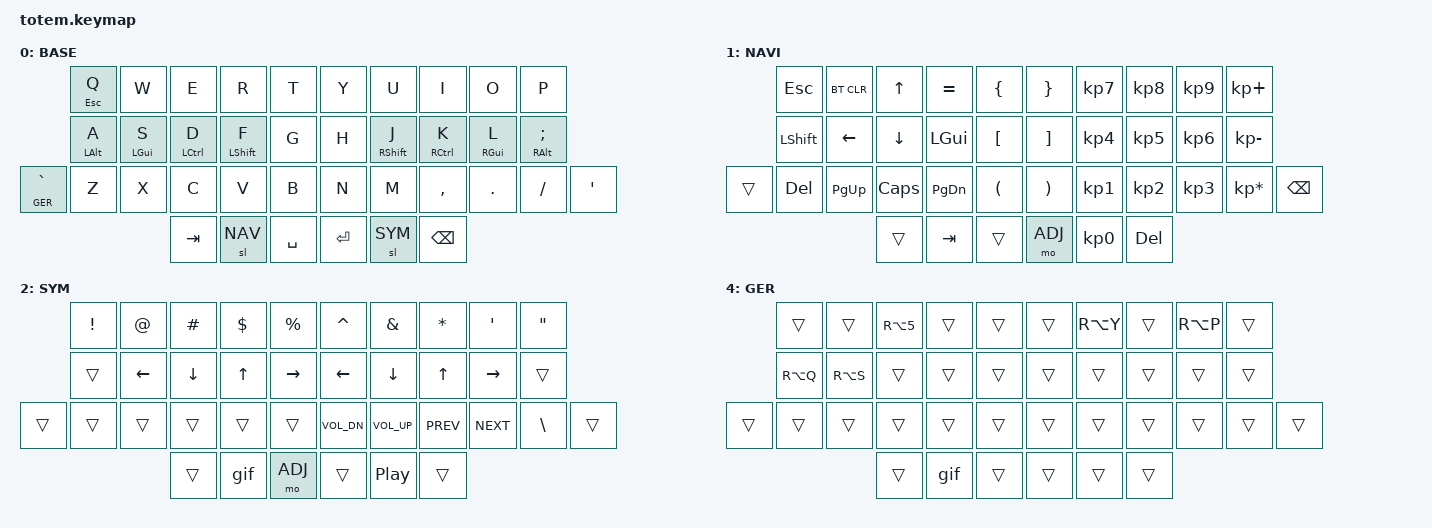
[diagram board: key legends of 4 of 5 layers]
//
//                                                        ▀▀▀▀▀     ▀▀▀▀▀          ▀▀█▀▀
//                                                        ▄▀▀▀▄  ▄  ▄▀▀▀▄  ▄  ▄▀▀▀▄  █  ▄▀▀▀▄
//                                                        █   █  █  █   █  █  █   █  █  █   █
//                                                         ▀▀▀   █   ▀▀▀   █   ▀▀▀   ▀   ▀▀▀
//                                                               █      ▄▄▄█▄▄▄    █   █  
//                                                               ▀      █  █  █     █▄█
//                                                             ▀▀▀▀▀    █  █  █      ▀
//                                                                      ▀  ▀  ▀
//
// ▄▄▄▄▄▄▄▄▄▄▄▄▄▄▄▄▄▄▄▄▄▄▄▄▄▄▄▄▄▄▄▄▄▄▄▄▄▄▄▄▄▄▄▄▄▄▄▄▄▄▄▄▄▄▄▄▄▄▄▄▄▄▄▄▄▄▄▄▄▄▄▄▄▄▄▄▄▄▄▄▄▄▄▄▄▄▄▄▄▄▄▄▄▄▄▄▄▄▄▄▄▄▄▄▄▄▄▄▄▄▄▄▄▄▄▄▄▄▄▄▄▄▄▄▄▄▄▄▄▄▄▄▄▄▄▄▄▄▄▄▄▄▄▄▄▄▄▄▄
       

#include <behaviors.dtsi>
#include <dt-bindings/zmk/keys.h>
#include <dt-bindings/zmk/bt.h>
#include <dt-bindings/zmk/outputs.h>

#define BASE 0
#define NAV  1
#define SYM  2
#define ADJ  3
#define GER  4

&mt {
  quick-tap-ms = <200>;
  global-quick-tap;
  flavor = "tap-preferred";
  tapping-term-ms = <170>;
};

/ {
    behaviors {
        hml: home_row_mod_left {
            compatible = "zmk,behavior-hold-tap";
            #binding-cells = <2>;
            flavor = "balanced";
            require-prior-idle-ms = <150>;
            tapping-term-ms = <280>;
            quick-tap-ms = <175>;
            bindings = <&kp>, <&kp>;
            hold-trigger-key-positions = <  5 6 7 8 9 15 16 17 18 19 26 27 28 29 30 31 35 36 37 >; // List of keys on the right side of the keyboard
            hold-trigger-on-release;
        };
        hmr: home_row_mod_right {
            compatible = "zmk,behavior-hold-tap";
            #binding-cells = <2>;
            flavor = "balanced";
            require-prior-idle-ms = <150>;
            tapping-term-ms = <280>;
            quick-tap-ms = <175>;
            bindings = <&kp>, <&kp>;
            hold-trigger-key-positions = < 0 1 2 3 4 10 11 12 13 14 20 21 22 23 24 25 32 33 34 >; // List of keys on the left side of the keyboard
            hold-trigger-on-release;
        };
    };
};

/ {
    combos {
            compatible = "zmk,combos";
            combo_esc {
                timeout-ms = <50>;
                key-positions = <0 1>;
                bindings = <&kp ESC>;
            };
    };

    macros {
        gif: gif {
            label = "giphy";
            compatible = "zmk,behavior-macro";
            #binding-cells = <0>;
            bindings
                = <&macro_press &kp LSHFT>
                , <&macro_tap &kp N2>
                , <&macro_release &kp LSHFT>
                , <&macro_tap &kp G &kp I &kp F>
                ;
        };
    };

        keymap {
                compatible = "zmk,keymap";
// ▄▄▄▄▄▄▄▄▄▄▄▄▄▄▄▄▄▄▄▄▄▄▄▄▄▄▄▄▄▄▄▄▄▄▄▄▄▄▄▄▄▄▄▄▄▄▄▄▄▄▄▄▄▄▄▄▄▄▄▄▄▄▄▄▄▄▄▄▄▄▄▄▄▄▄▄▄▄▄▄▄▄▄▄▄▄▄▄▄▄▄▄▄▄▄▄▄▄▄▄▄▄▄▄▄▄▄▄▄▄▄▄▄▄▄▄▄▄▄▄▄▄▄▄▄▄▄▄▄▄▄▄▄▄▄▄▄▄▄▄▄▄▄▄▄▄▄▄▄

                base_layer {
// ┏━━━━━━━━━━━━━━━━━━━━━━━━━━━━━━━━━━━━━━━┓
label= "BASE"                              ;
// ┗━━━━━━━━━━━━━━━━━━━━━━━━━━━━━━━━━━━━━━━┛
//             ┏━━━━━━━━━━━┳━━━━━━━━━━━┳━━━━━━━━━━━┳━━━━━━━━━━━┳━━━━━━━━━━━┓   ┏━━━━━━━━━━━┳━━━━━━━━━━━┳━━━━━━━━━━━┳━━━━━━━━━━━┳━━━━━━━━━━━┓
//             ┃     Q     ┃     W     ┃     E     ┃     R     ┃     T     ┃   ┃     Y     ┃     U     ┃     I     ┃     O     ┃     P     ┃
//             ┣━━━━━━━━━━━╋━━━━━━━━━━━╋━━━━━━━━━━━╋━━━━━━━━━━━╋━━━━━━━━━━━┫   ┣━━━━━━━━━━━╋━━━━━━━━━━━╋━━━━━━━━━━━╋━━━━━━━━━━━╋━━━━━━━━━━━┫
//             ┃     A     ┃     S     ┃     D     ┃     F     ┃     G     ┃   ┃     H     ┃     J     ┃     K     ┃     L     ┃     ;     ┃
// ┏━━━━━━━━━━━╋━━━━━━━━━━━╋━━━━━━━━━━━╋━━━━━━━━━━━╋━━━━━━━━━━━╋━━━━━━━━━━━┫   ┣━━━━━━━━━━━╋━━━━━━━━━━━╋━━━━━━━━━━━╋━━━━━━━━━━━╋━━━━━━━━━━━╋━━━━━━━━━━━┓
// ┃     `     ┃     Z     ┃     X     ┃     C     ┃     V     ┃     B     ┃   ┃     N     ┃     M     ┃     ,     ┃     .     ┃     /     ┃     '     ┃
// ┗━━━━━━━━━━━┻━━━━━━━━━━━┻━━━━━━━━━━━╋━━━━━━━━━━━╋━━━━━━━━━━━╋━━━━━━━━━━━┫   ┣━━━━━━━━━━━╋━━━━━━━━━━━╋━━━━━━━━━━━╋━━━━━━━━━━━┻━━━━━━━━━━━┻━━━━━━━━━━━┛
//                                     ┃    TAB    ┃    NAV    ┃    SPC    ┃   ┃   ENTER   ┃   SYM     ┃   BSPC    ┃
//                                     ┗━━━━━━━━━━━┻━━━━━━━━━━━┻━━━━━━━━━━━┛   ┗━━━━━━━━━━━┻━━━━━━━━━━━┻━━━━━━━━━━━┛
 bindings = <
// ╷           ╷           ╷           ╷           ╷           ╷           ╷   ╷           ╷           ╷           ╷           ╷           ╷           ╷

                &mt ESC Q    &kp W       &kp E        &kp R        &kp T           &kp Y       &kp U           &kp I        &kp O       &kp P
                &hml LALT A  &hml LGUI S &hml LCTRL D &hml LSHFT F &kp G           &kp H       &hmr RSHFT J    &hmr RCTRL K &hmr RGUI L &hmr RALT SEMI
&lt GER GRAVE   &kp Z        &kp X       &kp C        &kp V        &kp B           &kp N       &kp M           &kp COMMA    &kp DOT     &kp FSLH    &kp SINGLE_QUOTE
                                         &kp TAB      &sl NAV      &kp SPACE       &kp RET     &sl SYM         &kp BSPC
                        >;
                };

// ▄▄▄▄▄▄▄▄▄▄▄▄▄▄▄▄▄▄▄▄▄▄▄▄▄▄▄▄▄▄▄▄▄▄▄▄▄▄▄▄▄▄▄▄▄▄▄▄▄▄▄▄▄▄▄▄▄▄▄▄▄▄▄▄▄▄▄▄▄▄▄▄▄▄▄▄▄▄▄▄▄▄▄▄▄▄▄▄▄▄▄▄▄▄▄▄▄▄▄▄▄▄▄▄▄▄▄▄▄▄▄▄▄▄▄▄▄▄▄▄▄▄▄▄▄▄▄▄▄▄▄▄▄▄▄▄▄▄▄▄▄▄▄▄▄▄▄▄▄


                nav_layer {
// ┏━━━━━━━━━━━━━━━━━━━━━━━━━━━━━━━━━━━━━━━┓
label= "NAVI"                              ;
// ┗━━━━━━━━━━━━━━━━━━━━━━━━━━━━━━━━━━━━━━━┛
//             ┏━━━━━━━━━━━┳━━━━━━━━━━━┳━━━━━━━━━━━┳━━━━━━━━━━━┳━━━━━━━━━━━┓   ┏━━━━━━━━━━━┳━━━━━━━━━━━┳━━━━━━━━━━━┳━━━━━━━━━━━┳━━━━━━━━━━━┓
//             ┃           ┃           ┃     UP    ┃           ┃     {     ┃   ┃     }     ┃     7     ┃     8     ┃     9     ┃     +     ┃
//             ┣━━━━━━━━━━━╋━━━━━━━━━━━╋━━━━━━━━━━━╋━━━━━━━━━━━╋━━━━━━━━━━━┫   ┣━━━━━━━━━━━╋━━━━━━━━━━━╋━━━━━━━━━━━╋━━━━━━━━━━━╋━━━━━━━━━━━┫
//             ┃   SHIFT   ┃   LEFT    ┃    DOWN   ┃   LGUI    ┃     [     ┃   ┃     ]     ┃     4     ┃     5     ┃     6     ┃     -     ┃
// ┏━━━━━━━━━━━╋━━━━━━━━━━━╋━━━━━━━━━━━╋━━━━━━━━━━━╋━━━━━━━━━━━╋━━━━━━━━━━━┫   ┣━━━━━━━━━━━╋━━━━━━━━━━━╋━━━━━━━━━━━╋━━━━━━━━━━━╋━━━━━━━━━━━╋━━━━━━━━━━━┓
// ┃           ┃           ┃   P UP    ┃  C LOCK   ┃  P DOWN   ┃     (     ┃   ┃     )     ┃     1     ┃     2     ┃     3     ┃     *     ┃           ┃
// ┗━━━━━━━━━━━┻━━━━━━━━━━━┻━━━━━━━━━━━╋━━━━━━━━━━━╋━━━━━━━━━━━╋━━━━━━━━━━━┫   ┣━━━━━━━━━━━╋━━━━━━━━━━━╋━━━━━━━━━━━╋━━━━━━━━━━━┻━━━━━━━━━━━┻━━━━━━━━━━━┛
//                                     ┃           ┃           ┃           ┃   ┃    ADJ    ┃     0     ┃           ┃
//                                     ┗━━━━━━━━━━━┻━━━━━━━━━━━┻━━━━━━━━━━━┛   ┗━━━━━━━━━━━┻━━━━━━━━━━━┻━━━━━━━━━━━┛
 bindings = <
// ╷           ╷           ╷           ╷           ╷           ╷           ╷   ╷           ╷           ╷           ╷           ╷           ╷           ╷

                &kp ESC     &bt BT_CLR  &kp UP      &kp EQUAL   &kp LBRC        &kp RBRC    &kp KP_N7   &kp KP_N8   &kp KP_N9   &kp KP_PLUS
                &kp LSHFT   &kp LEFT    &kp DOWN    &kp LGUI    &kp LBKT        &kp RBKT    &kp KP_N4   &kp KP_N5   &kp KP_N6   &kp KP_MINUS
    &trans      &kp DEL     &kp PG_UP   &kp CAPS    &kp PG_DN   &kp LPAR        &kp RPAR    &kp KP_N1   &kp KP_N2   &kp KP_N3   &kp KP_MULTIPLY &kp BSPC      
                                        &trans      &kp TAB     &trans          &mo ADJ     &kp KP_N0   &kp DEL      
                        >;
                };

// ▄▄▄▄▄▄▄▄▄▄▄▄▄▄▄▄▄▄▄▄▄▄▄▄▄▄▄▄▄▄▄▄▄▄▄▄▄▄▄▄▄▄▄▄▄▄▄▄▄▄▄▄▄▄▄▄▄▄▄▄▄▄▄▄▄▄▄▄▄▄▄▄▄▄▄▄▄▄▄▄▄▄▄▄▄▄▄▄▄▄▄▄▄▄▄▄▄▄▄▄▄▄▄▄▄▄▄▄▄▄▄▄▄▄▄▄▄▄▄▄▄▄▄▄▄▄▄▄▄▄▄▄▄▄▄▄▄▄▄▄▄▄▄▄▄▄▄▄▄


                sim_layer {
// ┏━━━━━━━━━━━━━━━━━━━━━━━━━━━━━━━━━━━━━━━┓
label= "SYM"                               ;
// ┗━━━━━━━━━━━━━━━━━━━━━━━━━━━━━━━━━━━━━━━┛
//             ┏━━━━━━━━━━━┳━━━━━━━━━━━┳━━━━━━━━━━━┳━━━━━━━━━━━┳━━━━━━━━━━━┓   ┏━━━━━━━━━━━┳━━━━━━━━━━━┳━━━━━━━━━━━┳━━━━━━━━━━━┳━━━━━━━━━━━┓
//             ┃     !     ┃     @     ┃     #     ┃     $     ┃     %     ┃   ┃     ˆ     ┃     &     ┃     *     ┃     '     ┃     "     ┃
//             ┣━━━━━━━━━━━╋━━━━━━━━━━━╋━━━━━━━━━━━╋━━━━━━━━━━━╋━━━━━━━━━━━┫   ┣━━━━━━━━━━━╋━━━━━━━━━━━╋━━━━━━━━━━━╋━━━━━━━━━━━╋━━━━━━━━━━━┫
//             ┃           ┃    LEFT   ┃    DOWN   ┃     UP    ┃   RIGHT   ┃   ┃    LEFT   ┃    DOWN   ┃     UP    ┃   RIGHT   ┃           ┃
// ┏━━━━━━━━━━━╋━━━━━━━━━━━╋━━━━━━━━━━━╋━━━━━━━━━━━╋━━━━━━━━━━━╋━━━━━━━━━━━┫   ┣━━━━━━━━━━━╋━━━━━━━━━━━╋━━━━━━━━━━━╋━━━━━━━━━━━╋━━━━━━━━━━━╋━━━━━━━━━━━┓
// ┃           ┃           ┃           ┃           ┃           ┃           ┃   ┃   VOL-    ┃   VOL+    ┃   LAST    ┃   NEXT    ┃     \     ┃           ┃
// ┗━━━━━━━━━━━┻━━━━━━━━━━━┻━━━━━━━━━━━╋━━━━━━━━━━━╋━━━━━━━━━━━╋━━━━━━━━━━━┫   ┣━━━━━━━━━━━╋━━━━━━━━━━━╋━━━━━━━━━━━╋━━━━━━━━━━━┻━━━━━━━━━━━┻━━━━━━━━━━━┛
//                                     ┃           ┃    GIF    ┃    ADJ    ┃   ┃           ┃           ┃           ┃
//                                     ┗━━━━━━━━━━━┻━━━━━━━━━━━┻━━━━━━━━━━━┛   ┗━━━━━━━━━━━┻━━━━━━━━━━━┻━━━━━━━━━━━┛
 bindings = <
// ╷           ╷           ╷           ╷           ╷           ╷           ╷   ╷           ╷           ╷           ╷           ╷           ╷           ╷

                &kp EXCL    &kp AT      &kp HASH    &kp DLLR    &kp PRCNT       &kp CARET   &kp AMPS    &kp STAR   &kp SQT     &kp DQT       
                &trans      &kp LEFT    &kp DOWN    &kp UP      &kp RIGHT       &kp LEFT    &kp DOWN    &kp UP     &kp RIGHT   &trans
    &trans      &trans      &trans      &trans      &trans      &trans          &kp C_VOL_DN &kp C_VOL_UP &kp C_PREV    &kp C_NEXT  &kp BSLH   &trans         
                                        &trans      &gif        &mo ADJ         &trans      &kp C_PP    &trans      
                        >;
                };

// ▄▄▄▄▄▄▄▄▄▄▄▄▄▄▄▄▄▄▄▄▄▄▄▄▄▄▄▄▄▄▄▄▄▄▄▄▄▄▄▄▄▄▄▄▄▄▄▄▄▄▄▄▄▄▄▄▄▄▄▄▄▄▄▄▄▄▄▄▄▄▄▄▄▄▄▄▄▄▄▄▄▄▄▄▄▄▄▄▄▄▄▄▄▄▄▄▄▄▄▄▄▄▄▄▄▄▄▄▄▄▄▄▄▄▄▄▄▄▄▄▄▄▄▄▄▄▄▄▄▄▄▄▄▄▄▄▄▄▄▄▄▄▄▄▄▄▄▄▄


                adjust_layer {
// ┏━━━━━━━━━━━━━━━━━━━━━━━━━━━━━━━━━━━━━━━┓
label= "ADJ"                               ;
// ┗━━━━━━━━━━━━━━━━━━━━━━━━━━━━━━━━━━━━━━━┛
//             ┏━━━━━━━━━━━┳━━━━━━━━━━━┳━━━━━━━━━━━┳━━━━━━━━━━━┳━━━━━━━━━━━┓   ┏━━━━━━━━━━━┳━━━━━━━━━━━┳━━━━━━━━━━━┳━━━━━━━━━━━┳━━━━━━━━━━━┓
//             ┃   RESET   ┃ BT CLEAR  ┃  OUT TOG  ┃           ┃           ┃   ┃           ┃    F7     ┃    F8     ┃    F9     ┃    F12    ┃
//             ┣━━━━━━━━━━━╋━━━━━━━━━━━╋━━━━━━━━━━━╋━━━━━━━━━━━╋━━━━━━━━━━━┫   ┣━━━━━━━━━━━╋━━━━━━━━━━━╋━━━━━━━━━━━╋━━━━━━━━━━━╋━━━━━━━━━━━┫
//             ┃ BOOTLOAD  ┃ BT NEXT   ┃           ┃           ┃           ┃   ┃           ┃    F4     ┃    F5     ┃    F6     ┃    F11    ┃
// ┏━━━━━━━━━━━╋━━━━━━━━━━━╋━━━━━━━━━━━╋━━━━━━━━━━━╋━━━━━━━━━━━╋━━━━━━━━━━━┫   ┣━━━━━━━━━━━╋━━━━━━━━━━━╋━━━━━━━━━━━╋━━━━━━━━━━━╋━━━━━━━━━━━╋━━━━━━━━━━━┓
// ┃ STUDIO    ┃           ┃ BT PREV   ┃           ┃           ┃           ┃   ┃           ┃    F1     ┃    F2     ┃    F3     ┃    F10    ┃           ┃
// ┗━━━━━━━━━━━┻━━━━━━━━━━━┻━━━━━━━━━━━╋━━━━━━━━━━━╋━━━━━━━━━━━╋━━━━━━━━━━━┫   ┣━━━━━━━━━━━╋━━━━━━━━━━━╋━━━━━━━━━━━╋━━━━━━━━━━━┻━━━━━━━━━━━┻━━━━━━━━━━━┛
//                                     ┃           ┃           ┃           ┃   ┃           ┃           ┃           ┃
//                                     ┗━━━━━━━━━━━┻━━━━━━━━━━━┻━━━━━━━━━━━┛   ┗━━━━━━━━━━━┻━━━━━━━━━━━┻━━━━━━━━━━━┛
 bindings = <
// ╷           ╷           ╷           ╷           ╷           ╷           ╷   ╷           ╷           ╷           ╷           ╷           ╷           ╷

                &sys_reset  &bt BT_CLR &out OUT_TOG &trans      &trans          &trans      &kp F7      &kp F8      &kp F9      &kp F12
                &bootloader &bt BT_NXT  &trans      &trans      &trans          &trans      &kp F4      &kp F5      &kp F6      &kp F11  
    
&studio_unlock  &bt BT_PRV  &trans      &trans      &trans          &trans      &kp F1      &kp F2      &kp F3      &kp F10     &trans         
                                        &trans      &trans      &trans          &trans      &trans      &trans      
                        >;
                };

// ▄▄▄▄▄▄▄▄▄▄▄▄▄▄▄▄▄▄▄▄▄▄▄▄▄▄▄▄▄▄▄▄▄▄▄▄▄▄▄▄▄▄▄▄▄▄▄▄▄▄▄▄▄▄▄▄▄▄▄▄▄▄▄▄▄▄▄▄▄▄▄▄▄▄▄▄▄▄▄▄▄▄▄▄▄▄▄▄▄▄▄▄▄▄▄▄▄▄▄▄▄▄▄▄▄▄▄▄▄▄▄▄▄▄▄▄▄▄▄▄▄▄▄▄▄▄▄▄▄▄▄▄▄▄▄▄▄▄▄▄▄▄▄▄▄▄▄▄▄


                ger_layer {
// ┏━━━━━━━━━━━━━━━━━━━━━━━━━━━━━━━━━━━━━━━┓
label= "GER"                               ;
// ┗━━━━━━━━━━━━━━━━━━━━━━━━━━━━━━━━━━━━━━━┛
//             ┏━━━━━━━━━━━┳━━━━━━━━━━━┳━━━━━━━━━━━┳━━━━━━━━━━━┳━━━━━━━━━━━┓   ┏━━━━━━━━━━━┳━━━━━━━━━━━┳━━━━━━━━━━━┳━━━━━━━━━━━┳━━━━━━━━━━━┓
//             ┃           ┃           ┃     €     ┃           ┃           ┃   ┃           ┃     Ü     ┃           ┃     Ö     ┃           ┃
//             ┣━━━━━━━━━━━╋━━━━━━━━━━━╋━━━━━━━━━━━╋━━━━━━━━━━━╋━━━━━━━━━━━┫   ┣━━━━━━━━━━━╋━━━━━━━━━━━╋━━━━━━━━━━━╋━━━━━━━━━━━╋━━━━━━━━━━━┫
//             ┃     Ä     ┃     SZ    ┃           ┃           ┃           ┃   ┃           ┃           ┃           ┃           ┃           ┃
// ┏━━━━━━━━━━━╋━━━━━━━━━━━╋━━━━━━━━━━━╋━━━━━━━━━━━╋━━━━━━━━━━━╋━━━━━━━━━━━┫   ┣━━━━━━━━━━━╋━━━━━━━━━━━╋━━━━━━━━━━━╋━━━━━━━━━━━╋━━━━━━━━━━━╋━━━━━━━━━━━┓
// ┃           ┃           ┃           ┃           ┃           ┃           ┃   ┃           ┃           ┃           ┃           ┃           ┃           ┃
// ┗━━━━━━━━━━━┻━━━━━━━━━━━┻━━━━━━━━━━━╋━━━━━━━━━━━╋━━━━━━━━━━━╋━━━━━━━━━━━┫   ┣━━━━━━━━━━━╋━━━━━━━━━━━╋━━━━━━━━━━━╋━━━━━━━━━━━┻━━━━━━━━━━━┻━━━━━━━━━━━┛
//                                     ┃           ┃    GIF    ┃           ┃   ┃           ┃           ┃           ┃
//                                     ┗━━━━━━━━━━━┻━━━━━━━━━━━┻━━━━━━━━━━━┛   ┗━━━━━━━━━━━┻━━━━━━━━━━━┻━━━━━━━━━━━┛
 bindings = <
// ╷           ╷           ╷           ╷           ╷           ╷           ╷   ╷           ╷           ╷           ╷           ╷           ╷           ╷

                &trans      &trans      &kp RA(5)   &trans      &trans          &trans      &kp RA(Y)    &trans     &kp RA(P)     &trans       
                &kp RA(Q)   &kp RA(S)   &trans      &trans      &trans          &trans      &trans       &trans     &trans        &trans
    &trans      &trans      &trans      &trans      &trans      &trans          &trans      &trans       &trans     &trans       &trans   &trans         
                                        &trans      &gif        &trans          &trans      &trans    &trans      
                        >;
                };
        };
};
